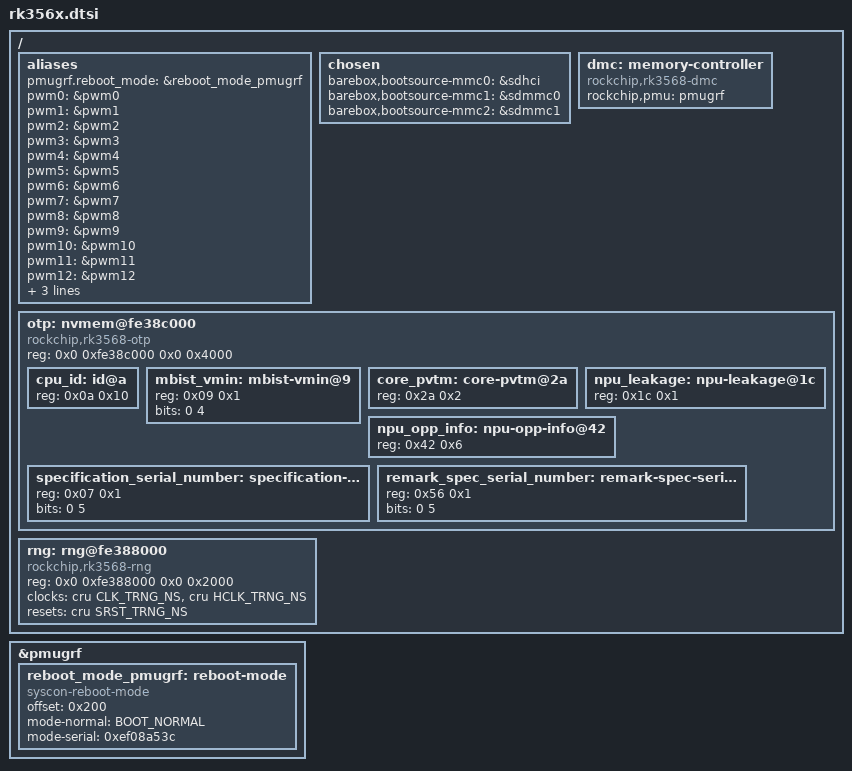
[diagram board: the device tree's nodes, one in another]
// SPDX-License-Identifier: (GPL-2.0+ OR MIT)

#include <dt-bindings/soc/rockchip,boot-mode.h>

/ {
	aliases {
		pmugrf.reboot_mode = &reboot_mode_pmugrf;
		pwm0 = &pwm0;
		pwm1 = &pwm1;
		pwm2 = &pwm2;
		pwm3 = &pwm3;
		pwm4 = &pwm4;
		pwm5 = &pwm5;
		pwm6 = &pwm6;
		pwm7 = &pwm7;
		pwm8 = &pwm8;
		pwm9 = &pwm9;
		pwm10 = &pwm10;
		pwm11 = &pwm11;
		pwm12 = &pwm12;
		pwm13 = &pwm13;
		pwm14 = &pwm14;
		pwm15 = &pwm15;
	};

	chosen {
		barebox,bootsource-mmc0 = &sdhci;
		barebox,bootsource-mmc1 = &sdmmc0;
		barebox,bootsource-mmc2 = &sdmmc1;
	};

	dmc: memory-controller {
		compatible = "rockchip,rk3568-dmc";
		rockchip,pmu = <&pmugrf>;
	};

	otp: nvmem@fe38c000 {
		compatible = "rockchip,rk3568-otp";
		reg = <0x0 0xfe38c000 0x0 0x4000>;
		#address-cells = <1>;
		#size-cells = <1>;

		cpu_id: id@a {
			reg = <0x0a 0x10>;
		};

		mbist_vmin: mbist-vmin@9 {
			reg = <0x09 0x1>;
			bits = <0 4>;
		};
		
		core_pvtm:core-pvtm@2a {
			reg = <0x2a 0x2>;
		};

		npu_leakage: npu-leakage@1c {
			reg = <0x1c 0x1>;
		};
		
		npu_opp_info: npu-opp-info@42 {
			reg = <0x42 0x6>;
		};

		specification_serial_number: specification-serial-number@7 {
			reg = <0x07 0x1>;
			bits = <0 5>;
		};

		remark_spec_serial_number: remark-spec-serial-number@56 {
			reg = <0x56 0x1>;
			bits = <0 5>;
		};
	};

	rng: rng@fe388000 {
		compatible = "rockchip,rk3568-rng", "rockchip,cryptov2-rng";
		reg = <0x0 0xfe388000 0x0 0x2000>;
		clocks = <&cru CLK_TRNG_NS>, <&cru HCLK_TRNG_NS>;
		clock-names = "trng_clk", "trng_hclk";
		resets = <&cru SRST_TRNG_NS>;
	};
};

&pmugrf {
	reboot_mode_pmugrf: reboot-mode {
		compatible = "syscon-reboot-mode";
		offset = <0x200>;
		mode-normal = <BOOT_NORMAL>;
		mode-serial = <0xef08a53c>; /* rk-usb-loader */
	};
};
